AUTOSAR XML (schema 4-2-2)
package /EB/SoftwareComponents
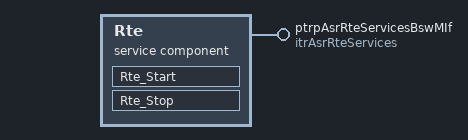
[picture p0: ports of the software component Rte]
  service sw component type Rte: category=ASR_Interfaces
    provide port ptrpAsrRteServicesBswMIf: provided-interface=itrAsrRteServices
    behavior Rte_IB: handle-termination-and-restart=NO-SUPPORT
      runnable Rte_Start
      runnable Rte_Stop
package /EB/TriggerInterfaces
  trigger interface itrAsrRteServices
    trigger Rte_Start: trigger-period={cse-code=1000, cse-code-factor=0}
    trigger Rte_Stop: trigger-period={cse-code=1000, cse-code-factor=0}
